# w600 register map
File version: v0.1
Registers are 32-bit, read-write, reset 0x0 unless marked. A register's access mark holds for its fields unless they carry their own. Offsets are from the block's base; [hi:lo] are bit positions; {n}, {i} and the like mark numbered series.

## rtc — real time
Base 0x40000600
0x0C rtc_r1 — 配置RTC 日时分秒值，配置使能定时
  [30:29] reserved — 保留
  [28:24] date — 日初值/日定时值
  [23:21] reserved — 保留
  [20:16] hour — 小时初值/小时定时值
  [15:14] reserved — 保留
  [13:8] reserved — 保留
  [7:6] reserved — 保留
  [0] rtc_int_en — 定时中断功能使能
    0=不使能; 1=使能
  [5:0] second — 秒初值/秒定时值
0x10 rtc_r2 — 配置RTC 年月值，配置使能计时
  [31:17] reserved — 保留
  [14:8] year — 年初值/年定时值
  [7:4] reserved — 保留
  [0] rtc_en — 计时功能使能位
    0=不使能; 1=使能
  [0] reserved — 保留
  [3:0] month — 月初值/月定时值

## timer
Base 0x40010E00
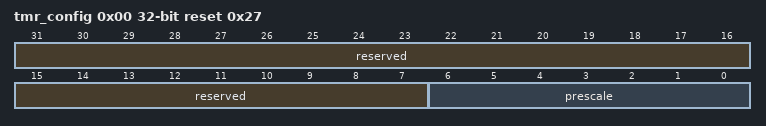
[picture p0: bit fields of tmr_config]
0x00 tmr_config reset 0x27 — 标准us 定时分频值，由总线时钟分频得到标准us 定时，该值等于 APB 总线频率（MHz）减一
  [31:7] reserved — 保留
  [6:0] prescale — 时钟分频配置prescale。例如： apb_clk=40MHz prescale = 40 – 1 = 8’d39
0x04 tmr_csr reset 0x6318C63 — 定时器控制寄存器
  [31:30] reserved — 保留
  [5n-1:5n-5] tmr{n}_csr (n=2..6) — ，同TMR1_CSR
  [0] tmr_int_status — 中断状态寄存器，写 1 清除
    0=Timer 无中断产生；; 1=Timer 产生中断；
  [0] tmr_int_en — 中断使能寄存器
    0=定时时间完成后不产生中断；; 1=定时时间完成后产生中断；
  [0] tmr_en
    0=定时器不工作；; 1=使能定时器
  [0] tmr_mode
    0=定时器重复定时；; 1=定时器只定时一次，定时完成后自动关闭；
  [0] tmr_unit
    0=定时单位为 us；; 1=定时单位为 ms；
{0x4+4i} tmr{i}_prd (i=1..6) — Timer{i} 定时值配置寄存器
  [31:0] tmr{i}_value — 配置定时器 {i} 的定时值

## uart0
Base 0x40010800
Same registers: uart1 0x40010A00
0x00 uart_line_ctrl reset 0xB — uart 通信的数据格式设置
  [31:8] reserved — 保留
  [0] uart_rx_enable — 接收使能，高有效
  [0] uart_tx_enable — 发送使能，高有效。
  [0] send_break_enable — 发送break 数据包。Uart 会在该为被置位后发送完一个break 数据包，发送完成后自动清 0。
  [0] parity — 极性
    0=偶校验; 1=奇校验
  [0] parity — en 奇偶检验使能，高有效
  [0] stop_bit_count — 个数
    0=1 个停止位; 1=2 个停止位
  [1:0] uart_bit_length — 比特长度。
    {v}={v+5}bit (v=0..3)
0x04 auto_flow_ctrl reset 0x14 — uart rts/cts 硬件流控设置
  [31:5] reserved — 保留
  [4:2] rts_trigger_level — 在afc_enable 有效时，决定何时需要将RTS 置无效。
    0=rxfifo 有 4 个以上字节 3’h1rxfifo 有 8 个以上字节 3’h2rxfifo 有 12 个以上字节 3’h3rxfifo 有 16 个以上字节 3’h4rxfifo 有 20 个以上字节 3’h5rxfifo 有 24 个以上字节 3’h6rxfifo 有 28 个以上字节; 7=rxfifo 有 31 个以上字节
  [0] rts_set — 当AFC_enable 无效时，软件可以通过设置此位来完成接收流量控制。当 AFC_enable 有效时，此位不关心。
  [0] afc_enable
    1=有效，接收条件rts 使用rts_trigger_level 控制产生。
0x08 dma_ctrl reset 0x24 — uart dma 传输模式设置
  [31:8] reserved — 保留
  [7:3] rxfifo_timeout_num — rxfifo 中存在数据小于rxfifo_trigger_level 情况下，如果 N 个包的时间内，没有接收到新的数据时，产生rxfifo timeout 中断。 该计时功能使能后，无论是第一次计时还是上一次计时完成，都只在接收到至少 1 个包后才开始计时
  [0] rxfifo_timeout_en — rxfifo 超时使能
  [0] rx_dma_enable — 接收DMA 使能，高有效。 0：表示接收过程使用中断。
  [0] tx_dma_enable — 发送DMA 使能，高有效。 0：表示发送过程使用中断。
0x0C uart_fifo_ctrl reset 0x14 — 设置 uart fifo 触发等级
  [31:6] reserved — 保留
  [5:4] rxfifo_trigger_level
    0=1byte; 1=4byte; 2=8byte 2’h316byte
  [3:2] txfifo_trigger_level
    0=empty; 1=4byte 2’h28byte; 3=16byte
  [0] rxfifo_reset — 复位rxfifo，将rxfifo 状态清空
  [0] txfifo_reset — 复位txfifo，将txfifo 状态清空
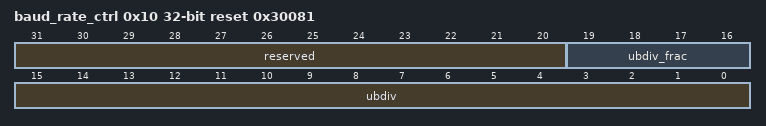
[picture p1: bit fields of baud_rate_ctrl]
0x10 baud_rate_ctrl reset 0x30081 — 设置uart 通信波特率
  [31:20] reserved — 保留
  [19:16] ubdiv_frac — 系统时钟除以 16 倍波特率时钟商的小数部分指示。具体值为frac×16 。 （参考章节 2.3.2，波特率计算方法）
  [15:0] ubdiv — 系统时钟除以 16 倍波特率时钟商的整数部分减 1。默认系统时钟为 40MHz，波特率为 19200。 （参考章节 2.3.2，波特率计算方法）
0x14 int_mask reset 0x1FF — 设置uart 需要使用的中断
  [31:9] reserved — 保留
  [0] overrun_error_int_mask — ， rxfifo 溢出中断屏蔽位，高有效。
  [0] parity_error_int_mask — ，奇偶检验中断屏蔽位，高有效。
  [0] frame_error_int_mask — ，数据帧出错中断屏蔽位，高有效。
  [0] break_detect_int_mask — ，break 信号检测中断屏蔽位，高有效。
  [0] cts_changed_indicate_mask — ，CTS 信号变化中断屏蔽位，高有效。
  [0] rxfifo_data_timeout_int_mask — ，rxfifo 接收数据超时中断屏蔽位，高有效。
  [0] rxfifo_trigger_level_int_mask — ，rxfifo 达到触发值中断屏蔽位，高有效。
  [0] txfifo_trigger_level_int_mask — ，txfifo 达到触发值中断屏蔽位，高有效。
  [0] txfifo_empty_int_mask — ，txfifo 为空中断屏蔽位，高有效。
0x18 int_src — uart 中断状态指示
  [31:9] reserved — 保留
  [0] overrun_error_rxfifo — 出现溢出。 软件主动写 1 清 0。
  [0] parity_error — 接收到的包校验位错误。 DMA 情况下，此中断仍会产生。但DMA 操作不关心此中断。软件主动写 1 清 0。
  [0] frame_error — 接收到的包停止位错误。 DMA 情况下，此中断仍会产生。但DMA 操作不关心此中断。软件主动写 1 清 0。
  [0] break_detect — 接收到break 包。 DMA 情况下，此中断仍会产生。但DMA 操作不关心此中断。 软件主动写 1 清 0。
  [0] cts_changed — cts 信号变化则产生此中断。软件主动写 1 清 0。
  [0] rxfifo_data_timeout — rxfifo 中数据长度小于rxfifo trigger level 但N 个数据周期没有接收到任何数据，则产生中断。 软件主动写 1 清 0。
  [0] rxfifo_trigger_level_interrupt — 当rxfifo 中数据个数由小于rxfifo trigger level 中指定的数变成大于或等于该数时，产生此中断。 此时应该根据rxfifo count 确定当前数据帧大小。 软件主动写 1 清 0。
  [0] txfifo_trigger_level_interrupt — 当txfifo 中数据个数由大于txfifo trigger level 中指定的数变成小于或等于该数时，产生中断。 软件主动写 1 清 0。
  [0] tx_fifo_empty_interrupt — 当发送完成当前包，并且txfifo 为空时，产生此中断。软件主动写 1 清 0。
0x1C fifo_status reset 0x1000 — fifo 状态，cts 状态查询
  [31:13] reserved — 保留
  [11:6] rxfifo_count — rxfifo 中数据个数
  [0] cts_status — 当前cts 的状态
  [5:0] txfifo_count — txfifo 中数据个数
0x20 tx_data_window
  [31:0] tx_data_window — 发送数据起始地址。 注意：uart 发送与接收数据只支持字节操作，当采用 burst 传输时，有可能使用字节地址递增的方式，设计中最多支持 16-burst 的操作，即 16byte。因此从发送/接收起始地址后共 16byte（4 个字）都保留为发送/接收数据窗口。
0x30 rx_data_window ro
  [31:0] rx_data_window — 接收数据起始地址。 注意：uart 发送与接收数据只支持字节操作，当采用 burst 传输时，有可能使用字节地址递增的方式，设计中最多支持 16-burst 的操作，即 16byte。因此从发送/接收起始地址后共 16byte（4 个字）都保留为发送/接收数据窗口。

## watchdog
Base 0x40011000
0x00 wd_ld reset 0xFFFFFFFF — 配置定时值，用于重复加载
  [31:0] conf_en — 配置定时值，用于重复加载 此寄存器的值以APB 时钟为计数单位。 例如：以APB 时钟为 40MHZ，则定时值最大时长约 107s 左右，即 0FFFFFFFF/40000000
0x04 wd_val ro reset 0xFFFFFFFF — 获取当前定时器的值
  [31:0] timer_value — 获取当前定时器的值 要计算剩余时间，只要读取当前值即可。 要计算已经过去的时间，只要把寄存器WD_LD 的值减去寄存器WD_VAL 的值即可
0x08 wd_ctrl — 控制寄存器
  [31:2] reserved — 保留
  [0] reset_en — 复位使能位
    0=WDG 复位条件产生时，不产生复位信号; 1=WDG 复位条件产生时，产生复位信号
  [0] timer_en — 定时使能位
    0=定时器不工作; 1=定时器工作，产生周期性中断
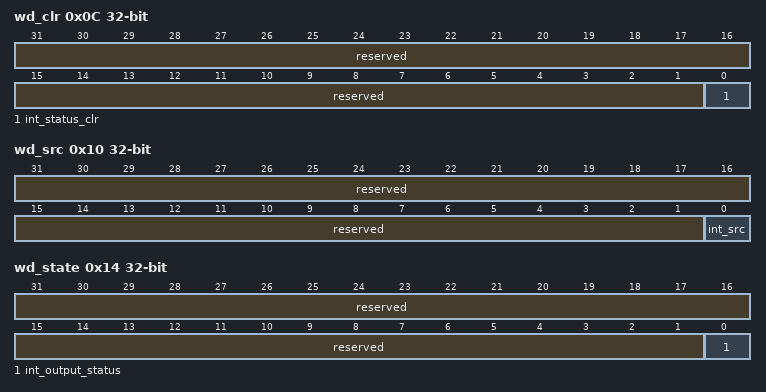
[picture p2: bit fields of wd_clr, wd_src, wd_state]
0x0C wd_clr — 中断清除寄存器
  [31:1] reserved — 保留
  [0] int_status_clr — 中断状态清除位，写任意值清除当前中断状态
0x10 wd_src ro — 中断源寄存器
  [31:1] reserved — 保留
  [0] int_src — 中断源寄存器，定时器功能打开，会同时产生该中断
0x14 wd_state ro — 中断输出状态寄存器
  [31:1] reserved — 保留
  [0] int_output_status — 中断输出状态寄存器。该中断在定时器关闭后不产生，但WD_SRC 可能为 1
